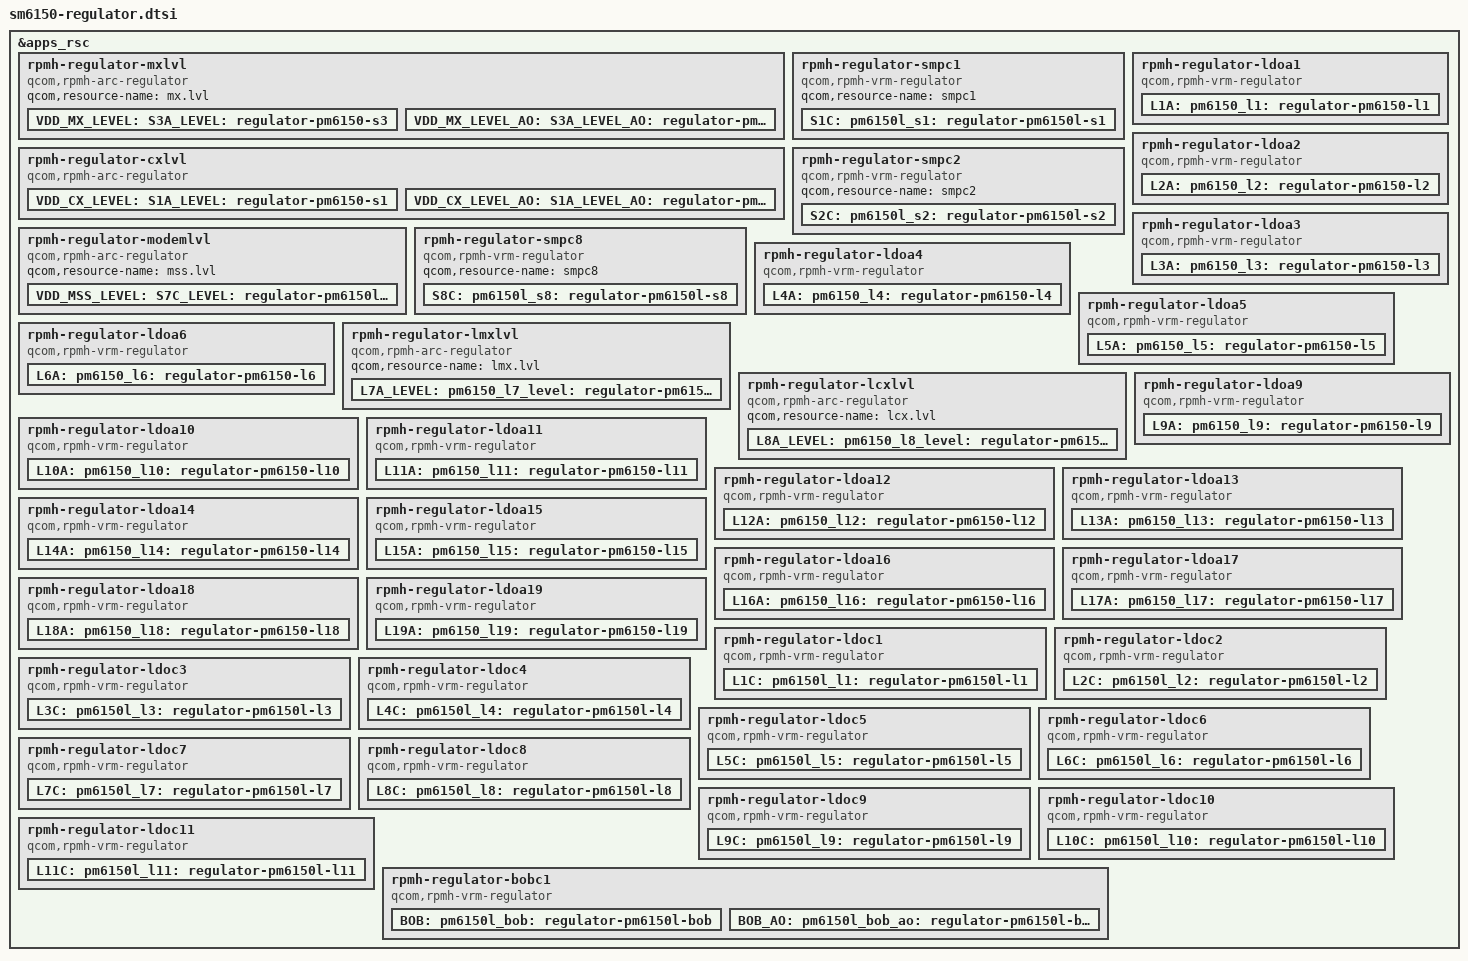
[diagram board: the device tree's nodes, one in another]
#include <dt-bindings/regulator/qcom,rpmh-regulator-levels.h>

&apps_rsc {
	/* RPMh regulators: */

	/* pm6150 S3 - VDD_MX supply */
	rpmh-regulator-mxlvl {
		compatible = "qcom,rpmh-arc-regulator";
		qcom,resource-name = "mx.lvl";

		VDD_MX_LEVEL:
		S3A_LEVEL: pm6150_s3_level: regulator-pm6150-s3 {
			regulator-name = "pm6150_s3_level";
			qcom,set = <RPMH_REGULATOR_SET_ALL>;
			regulator-min-microvolt =
					<RPMH_REGULATOR_LEVEL_RETENTION>;
			regulator-max-microvolt =
					<RPMH_REGULATOR_LEVEL_MAX>;
			qcom,init-voltage-level =
					<RPMH_REGULATOR_LEVEL_RETENTION>;
		};

		VDD_MX_LEVEL_AO:
		S3A_LEVEL_AO: pm6150_s3_level_ao: regulator-pm6150-s3-level-ao {
			regulator-name = "pm6150_s3_level_ao";
			qcom,set = <RPMH_REGULATOR_SET_ACTIVE>;
			regulator-min-microvolt =
					<RPMH_REGULATOR_LEVEL_RETENTION>;
			regulator-max-microvolt =
					<RPMH_REGULATOR_LEVEL_MAX>;
			qcom,init-voltage-level =
					<RPMH_REGULATOR_LEVEL_RETENTION>;
		};
	};

	/* pm6150 S1 - VDD_CX supply */
	rpmh-regulator-cxlvl {
		compatible = "qcom,rpmh-arc-regulator";
		qcom,resource-name = "cx.lvl";
		pm6150_s1_level-parent-supply = <&VDD_MX_LEVEL>;
		pm6150_s1_level_ao-parent-supply = <&VDD_MX_LEVEL_AO>;

		VDD_CX_LEVEL:
		S1A_LEVEL: pm6150_s1_level: regulator-pm6150-s1 {
			regulator-name = "pm6150_s1_level";
			qcom,set = <RPMH_REGULATOR_SET_ALL>;
			regulator-min-microvolt =
					<RPMH_REGULATOR_LEVEL_RETENTION>;
			regulator-max-microvolt =
					<RPMH_REGULATOR_LEVEL_MAX>;
			qcom,init-voltage-level =
					<RPMH_REGULATOR_LEVEL_RETENTION>;
			qcom,min-dropout-voltage-level = <(-1)>;
		};

		VDD_CX_LEVEL_AO:
		S1A_LEVEL_AO: pm6150_s1_level_ao: regulator-pm6150-s1-level-ao {
			qcom,set = <RPMH_REGULATOR_SET_ACTIVE>;
			regulator-name = "pm6150_s1_level_ao";
			regulator-min-microvolt =
					<RPMH_REGULATOR_LEVEL_RETENTION>;
			regulator-max-microvolt =
					<RPMH_REGULATOR_LEVEL_MAX>;
			qcom,init-voltage-level =
					<RPMH_REGULATOR_LEVEL_RETENTION>;
			qcom,min-dropout-voltage-level = <(-1)>;
		};
	};

	rpmh-regulator-smpc1 {
		compatible = "qcom,rpmh-vrm-regulator";
		qcom,resource-name = "smpc1";
		S1C: pm6150l_s1: regulator-pm6150l-s1 {
			regulator-name = "pm6150l_s1";
			qcom,set = <RPMH_REGULATOR_SET_ALL>;
			regulator-min-microvolt = <1128000>;
			regulator-max-microvolt = <1128000>;
			qcom,init-voltage = <1128000>;
		};
	};

	rpmh-regulator-smpc2 {
		compatible = "qcom,rpmh-vrm-regulator";
		qcom,resource-name = "smpc2";
		S2C: pm6150l_s2: regulator-pm6150l-s2 {
			regulator-name = "pm6150l_s2";
			qcom,set = <RPMH_REGULATOR_SET_ALL>;
			regulator-min-microvolt = <348000>;
			regulator-max-microvolt = <648000>;
			qcom,init-voltage = <348000>;
		};
	};

	/* pm6150l S7 - VDD_MSS supply */
	rpmh-regulator-modemlvl {
		compatible = "qcom,rpmh-arc-regulator";
		qcom,resource-name = "mss.lvl";

		VDD_MSS_LEVEL:
		S7C_LEVEL: pm6150l_s7_level: regulator-pm6150l-s7 {
			regulator-name = "pm6150l_s7_level";
			qcom,set = <RPMH_REGULATOR_SET_ALL>;
			regulator-min-microvolt =
					<RPMH_REGULATOR_LEVEL_RETENTION>;
			regulator-max-microvolt =
					<RPMH_REGULATOR_LEVEL_MAX>;
			qcom,init-voltage-level =
					<RPMH_REGULATOR_LEVEL_RETENTION>;
		};
	};

	rpmh-regulator-smpc8 {
		compatible = "qcom,rpmh-vrm-regulator";
		qcom,resource-name = "smpc8";
		S8C: pm6150l_s8: regulator-pm6150l-s8 {
			regulator-name = "pm6150l_s8";
			qcom,set = <RPMH_REGULATOR_SET_ALL>;
			regulator-min-microvolt = <1200000>;
			regulator-max-microvolt = <1400000>;
			qcom,init-voltage = <1200000>;
		};
	};

	rpmh-regulator-ldoa1 {
		compatible = "qcom,rpmh-vrm-regulator";
		qcom,resource-name = "ldoa1";
		qcom,regulator-type = "pmic5-ldo";
		qcom,supported-modes =
				<RPMH_REGULATOR_MODE_LPM
				RPMH_REGULATOR_MODE_HPM>;
		qcom,mode-threshold-currents = <0 1>;
		L1A: pm6150_l1: regulator-pm6150-l1 {
			regulator-name = "pm6150_l1";
			qcom,set = <RPMH_REGULATOR_SET_ALL>;
			regulator-min-microvolt = <1200000>;
			regulator-max-microvolt = <1252000>;
			qcom,init-voltage = <1200000>;
		};
	};

	rpmh-regulator-ldoa2 {
		compatible = "qcom,rpmh-vrm-regulator";
		qcom,resource-name = "ldoa2";
		qcom,regulator-type = "pmic5-ldo";
		qcom,supported-modes =
				<RPMH_REGULATOR_MODE_LPM
				RPMH_REGULATOR_MODE_HPM>;
		qcom,mode-threshold-currents = <0 1>;
		L2A: pm6150_l2: regulator-pm6150-l2 {
			regulator-name = "pm6150_l2";
			qcom,set = <RPMH_REGULATOR_SET_ALL>;
			regulator-min-microvolt = <1000000>;
			regulator-max-microvolt = <1050000>;
			qcom,init-voltage = <1000000>;
			qcom,init-mode = <RPMH_REGULATOR_MODE_LPM>;
		};
	};

	rpmh-regulator-ldoa3 {
		compatible = "qcom,rpmh-vrm-regulator";
		qcom,resource-name = "ldoa3";
		qcom,regulator-type = "pmic5-ldo";
		qcom,supported-modes =
				<RPMH_REGULATOR_MODE_LPM
				RPMH_REGULATOR_MODE_HPM>;
		qcom,mode-threshold-currents = <0 1>;
		L3A: pm6150_l3: regulator-pm6150-l3 {
			regulator-name = "pm6150_l3";
			qcom,set = <RPMH_REGULATOR_SET_ALL>;
			regulator-min-microvolt = <1000000>;
			regulator-max-microvolt = <1060000>;
			qcom,init-voltage = <1000000>;
			qcom,init-mode = <RPMH_REGULATOR_MODE_LPM>;
		};
	};

	rpmh-regulator-ldoa4 {
		compatible = "qcom,rpmh-vrm-regulator";
		qcom,resource-name = "ldoa4";
		qcom,regulator-type = "pmic5-ldo";
		qcom,supported-modes =
				<RPMH_REGULATOR_MODE_LPM
				RPMH_REGULATOR_MODE_HPM>;
		qcom,mode-threshold-currents = <0 1>;
		proxy-supply = <&pm6150_l4>;
		L4A: pm6150_l4: regulator-pm6150-l4 {
			regulator-name = "pm6150_l4";
			qcom,set = <RPMH_REGULATOR_SET_ALL>;
			regulator-min-microvolt = <875000>;
			regulator-max-microvolt = <975000>;
			qcom,init-voltage = <875000>;
			qcom,init-mode = <RPMH_REGULATOR_MODE_LPM>;
			qcom,proxy-consumer-enable;
			qcom,proxy-consumer-current = <23800>;
		};
	};

	rpmh-regulator-ldoa5 {
		compatible = "qcom,rpmh-vrm-regulator";
		qcom,resource-name = "ldoa5";
		qcom,regulator-type = "pmic5-ldo";
		qcom,supported-modes =
				<RPMH_REGULATOR_MODE_LPM
				RPMH_REGULATOR_MODE_HPM>;
		qcom,mode-threshold-currents = <0 1>;
		L5A: pm6150_l5: regulator-pm6150-l5 {
			regulator-name = "pm6150_l5";
			qcom,set = <RPMH_REGULATOR_SET_ALL>;
			regulator-min-microvolt = <2500000>;
			regulator-max-microvolt = <2970000>;
			qcom,init-voltage = <2500000>;
			qcom,init-mode = <RPMH_REGULATOR_MODE_LPM>;
		};
	};

	rpmh-regulator-ldoa6 {
		compatible = "qcom,rpmh-vrm-regulator";
		qcom,resource-name = "ldoa6";
		qcom,regulator-type = "pmic5-ldo";
		qcom,supported-modes =
				<RPMH_REGULATOR_MODE_LPM
				RPMH_REGULATOR_MODE_HPM>;
		qcom,mode-threshold-currents = <0 1>;
		L6A: pm6150_l6: regulator-pm6150-l6 {
			regulator-name = "pm6150_l6";
			qcom,set = <RPMH_REGULATOR_SET_ALL>;
			regulator-min-microvolt = <600000>;
			regulator-max-microvolt = <650000>;
			qcom,init-voltage = <600000>;
			qcom,init-mode = <RPMH_REGULATOR_MODE_LPM>;
		};
	};

	/* pm6150 L7 - LPI_MX supply */
	rpmh-regulator-lmxlvl {
		compatible = "qcom,rpmh-arc-regulator";
		qcom,resource-name = "lmx.lvl";
		L7A_LEVEL: pm6150_l7_level: regulator-pm6150-l7 {
			regulator-name = "pm6150_l7_level";
			qcom,set = <RPMH_REGULATOR_SET_ALL>;
			regulator-min-microvolt =
					<RPMH_REGULATOR_LEVEL_RETENTION>;
			regulator-max-microvolt =
					<RPMH_REGULATOR_LEVEL_MAX>;
			qcom,init-voltage-level =
					<RPMH_REGULATOR_LEVEL_RETENTION>;
		};
	};

	/* pm6150 L8 - LPI_CX supply */
	rpmh-regulator-lcxlvl {
		compatible = "qcom,rpmh-arc-regulator";
		qcom,resource-name = "lcx.lvl";
		L8A_LEVEL: pm6150_l8_level: regulator-pm6150-l8 {
			regulator-name = "pm6150_l8_level";
			qcom,set = <RPMH_REGULATOR_SET_ALL>;
			regulator-min-microvolt =
					<RPMH_REGULATOR_LEVEL_RETENTION>;
			regulator-max-microvolt =
					<RPMH_REGULATOR_LEVEL_MAX>;
			qcom,init-voltage-level =
					<RPMH_REGULATOR_LEVEL_RETENTION>;
		};
	};

	/* pm6150 L9 - WCSS_CX supply */
	rpmh-regulator-ldoa9 {
		compatible = "qcom,rpmh-vrm-regulator";
		qcom,resource-name = "ldoa9";
		qcom,regulator-type = "pmic5-ldo";
		qcom,supported-modes =
				<RPMH_REGULATOR_MODE_LPM
				RPMH_REGULATOR_MODE_HPM>;
		qcom,mode-threshold-currents = <0 1>;
		L9A: pm6150_l9: regulator-pm6150-l9 {
			regulator-name = "pm6150_l9";
			qcom,set = <RPMH_REGULATOR_SET_ALL>;
			regulator-min-microvolt = <400000>;
			regulator-max-microvolt = <728000>;
			qcom,init-voltage = <400000>;
			qcom,init-mode = <RPMH_REGULATOR_MODE_LPM>;
		};
	};

	rpmh-regulator-ldoa10 {
		compatible = "qcom,rpmh-vrm-regulator";
		qcom,resource-name = "ldoa10";
		qcom,regulator-type = "pmic5-ldo";
		qcom,supported-modes =
				<RPMH_REGULATOR_MODE_LPM
				RPMH_REGULATOR_MODE_HPM>;
		qcom,mode-threshold-currents = <0 1>;
		L10A: pm6150_l10: regulator-pm6150-l10 {
			regulator-name = "pm6150_l10";
			qcom,set = <RPMH_REGULATOR_SET_ALL>;
			regulator-min-microvolt = <1800000>;
			regulator-max-microvolt = <1829000>;
			qcom,init-voltage = <1800000>;
			qcom,init-mode = <RPMH_REGULATOR_MODE_LPM>;
		};
	};

	rpmh-regulator-ldoa11 {
		compatible = "qcom,rpmh-vrm-regulator";
		qcom,resource-name = "ldoa11";
		qcom,regulator-type = "pmic5-ldo";
		qcom,supported-modes =
				<RPMH_REGULATOR_MODE_LPM
				RPMH_REGULATOR_MODE_HPM>;
		qcom,mode-threshold-currents = <0 1>;
		L11A: pm6150_l11: regulator-pm6150-l11 {
			regulator-name = "pm6150_l11";
			qcom,set = <RPMH_REGULATOR_SET_ALL>;
			regulator-min-microvolt = <1800000>;
			regulator-max-microvolt = <1890000>;
			qcom,init-voltage = <1800000>;
			qcom,init-mode = <RPMH_REGULATOR_MODE_LPM>;
		};
	};

	rpmh-regulator-ldoa12 {
		compatible = "qcom,rpmh-vrm-regulator";
		qcom,resource-name = "ldoa12";
		qcom,regulator-type = "pmic5-ldo";
		qcom,supported-modes =
				<RPMH_REGULATOR_MODE_LPM
				RPMH_REGULATOR_MODE_HPM>;
		qcom,mode-threshold-currents = <0 1>;
		L12A: pm6150_l12: regulator-pm6150-l12 {
			regulator-name = "pm6150_l12";
			qcom,set = <RPMH_REGULATOR_SET_ALL>;
			regulator-min-microvolt = <1800000>;
			regulator-max-microvolt = <1950000>;
			qcom,init-voltage = <1800000>;
			qcom,init-mode = <RPMH_REGULATOR_MODE_LPM>;
		};
	};

	rpmh-regulator-ldoa13 {
		compatible = "qcom,rpmh-vrm-regulator";
		qcom,resource-name = "ldoa13";
		qcom,regulator-type = "pmic5-ldo";
		qcom,supported-modes =
				<RPMH_REGULATOR_MODE_LPM
				RPMH_REGULATOR_MODE_HPM>;
		qcom,mode-threshold-currents = <0 1>;
		proxy-supply = <&pm6150_l13>;
		L13A: pm6150_l13: regulator-pm6150-l13 {
			regulator-name = "pm6150_l13";
			qcom,set = <RPMH_REGULATOR_SET_ALL>;
			regulator-min-microvolt = <1800000>;
			regulator-max-microvolt = <1900000>;
			qcom,init-voltage = <1800000>;
			qcom,init-mode = <RPMH_REGULATOR_MODE_LPM>;
			qcom,proxy-consumer-enable;
			qcom,proxy-consumer-current = <115000>;
		};
	};

	rpmh-regulator-ldoa14 {
		compatible = "qcom,rpmh-vrm-regulator";
		qcom,resource-name = "ldoa14";
		qcom,regulator-type = "pmic5-ldo";
		qcom,supported-modes =
				<RPMH_REGULATOR_MODE_LPM
				RPMH_REGULATOR_MODE_HPM>;
		qcom,mode-threshold-currents = <0 1>;
		L14A: pm6150_l14: regulator-pm6150-l14 {
			regulator-name = "pm6150_l14";
			qcom,set = <RPMH_REGULATOR_SET_ALL>;
			regulator-min-microvolt = <1800000>;
			regulator-max-microvolt = <1850000>;
			qcom,init-voltage = <1800000>;
			qcom,init-mode = <RPMH_REGULATOR_MODE_LPM>;
		};
	};

	rpmh-regulator-ldoa15 {
		compatible = "qcom,rpmh-vrm-regulator";
		qcom,resource-name = "ldoa15";
		qcom,regulator-type = "pmic5-ldo";
		qcom,supported-modes =
				<RPMH_REGULATOR_MODE_LPM
				RPMH_REGULATOR_MODE_HPM>;
		qcom,mode-threshold-currents = <0 1>;
		L15A: pm6150_l15: regulator-pm6150-l15 {
			regulator-name = "pm6150_l15";
			qcom,set = <RPMH_REGULATOR_SET_ALL>;
			regulator-min-microvolt = <1800000>;
			regulator-max-microvolt = <1900000>;
			qcom,init-voltage = <1800000>;
			qcom,init-mode = <RPMH_REGULATOR_MODE_LPM>;
		};
	};

	rpmh-regulator-ldoa16 {
		compatible = "qcom,rpmh-vrm-regulator";
		qcom,resource-name = "ldoa16";
		qcom,regulator-type = "pmic5-ldo";
		qcom,supported-modes =
				<RPMH_REGULATOR_MODE_LPM
				RPMH_REGULATOR_MODE_HPM>;
		qcom,mode-threshold-currents = <0 1>;
		L16A: pm6150_l16: regulator-pm6150-l16 {
			regulator-name = "pm6150_l16";
			qcom,set = <RPMH_REGULATOR_SET_ALL>;
			regulator-min-microvolt = <2430000>;
			regulator-max-microvolt = <2970000>;
			qcom,init-voltage = <2430000>;
			qcom,init-mode = <RPMH_REGULATOR_MODE_LPM>;
		};
	};

	rpmh-regulator-ldoa17 {
		compatible = "qcom,rpmh-vrm-regulator";
		qcom,resource-name = "ldoa17";
		qcom,regulator-type = "pmic5-ldo";
		qcom,supported-modes =
				<RPMH_REGULATOR_MODE_LPM
				RPMH_REGULATOR_MODE_HPM>;
		qcom,mode-threshold-currents = <0 1>;
		L17A: pm6150_l17: regulator-pm6150-l17 {
			regulator-name = "pm6150_l17";
			qcom,set = <RPMH_REGULATOR_SET_ALL>;
			regulator-min-microvolt = <3000000>;
			regulator-max-microvolt = <3230000>;
			qcom,init-voltage = <3000000>;
			qcom,init-mode = <RPMH_REGULATOR_MODE_LPM>;
		};
	};

	rpmh-regulator-ldoa18 {
		compatible = "qcom,rpmh-vrm-regulator";
		qcom,resource-name = "ldoa18";
		qcom,regulator-type = "pmic5-ldo";
		qcom,supported-modes =
				<RPMH_REGULATOR_MODE_LPM
				RPMH_REGULATOR_MODE_HPM>;
		qcom,mode-threshold-currents = <0 1>;
		L18A: pm6150_l18: regulator-pm6150-l18 {
			regulator-name = "pm6150_l18";
			qcom,set = <RPMH_REGULATOR_SET_ALL>;
			regulator-min-microvolt = <3000000>;
			regulator-max-microvolt = <3008000>;
			qcom,init-voltage = <3000000>;
			qcom,init-mode = <RPMH_REGULATOR_MODE_LPM>;
		};
	};

	rpmh-regulator-ldoa19 {
		compatible = "qcom,rpmh-vrm-regulator";
		qcom,resource-name = "ldoa19";
		qcom,regulator-type = "pmic5-ldo";
		qcom,supported-modes =
				<RPMH_REGULATOR_MODE_LPM
				RPMH_REGULATOR_MODE_HPM>;
		qcom,mode-threshold-currents = <0 1>;
		L19A: pm6150_l19: regulator-pm6150-l19 {
			regulator-name = "pm6150_l19";
			qcom,set = <RPMH_REGULATOR_SET_ALL>;
			regulator-min-microvolt = <2700000>;
			regulator-max-microvolt = <3008000>;
			qcom,init-voltage = <2700000>;
			qcom,init-mode = <RPMH_REGULATOR_MODE_LPM>;
		};
	};

	rpmh-regulator-ldoc1 {
		compatible = "qcom,rpmh-vrm-regulator";
		qcom,resource-name = "ldoc1";
		qcom,regulator-type = "pmic5-ldo";
		qcom,supported-modes =
				<RPMH_REGULATOR_MODE_LPM
				RPMH_REGULATOR_MODE_HPM>;
		qcom,mode-threshold-currents = <0 10000>;
		L1C: pm6150l_l1: regulator-pm6150l-l1 {
			regulator-name = "pm6150l_l1";
			qcom,set = <RPMH_REGULATOR_SET_ALL>;
			regulator-min-microvolt = <1800000>;
			regulator-max-microvolt = <1900000>;
			qcom,init-voltage = <1800000>;
			qcom,init-mode = <RPMH_REGULATOR_MODE_LPM>;
		};
	};

	rpmh-regulator-ldoc2 {
		compatible = "qcom,rpmh-vrm-regulator";
		qcom,resource-name = "ldoc2";
		qcom,regulator-type = "pmic5-ldo";
		qcom,supported-modes =
				<RPMH_REGULATOR_MODE_LPM
				RPMH_REGULATOR_MODE_HPM>;
		qcom,mode-threshold-currents = <0 10000>;
		L2C: pm6150l_l2: regulator-pm6150l-l2 {
			regulator-name = "pm6150l_l2";
			qcom,set = <RPMH_REGULATOR_SET_ALL>;
			regulator-min-microvolt = <1304000>;
			regulator-max-microvolt = <1304000>;
			qcom,init-voltage = <1304000>;
			qcom,init-mode = <RPMH_REGULATOR_MODE_LPM>;
		};
	};

	rpmh-regulator-ldoc3 {
		compatible = "qcom,rpmh-vrm-regulator";
		qcom,resource-name = "ldoc3";
		qcom,regulator-type = "pmic5-ldo";
		qcom,supported-modes =
				<RPMH_REGULATOR_MODE_LPM
				RPMH_REGULATOR_MODE_HPM>;
		qcom,mode-threshold-currents = <0 1>;
		proxy-supply = <&pm6150l_l3>;
		L3C: pm6150l_l3: regulator-pm6150l-l3 {
			regulator-name = "pm6150l_l3";
			qcom,set = <RPMH_REGULATOR_SET_ALL>;
			regulator-min-microvolt = <1232000>;
			regulator-max-microvolt = <1260000>;
			qcom,init-voltage = <1232000>;
			qcom,init-mode = <RPMH_REGULATOR_MODE_LPM>;
			qcom,proxy-consumer-enable;
			qcom,proxy-consumer-current = <51800>;
		};
	};

	rpmh-regulator-ldoc4 {
		compatible = "qcom,rpmh-vrm-regulator";
		qcom,resource-name = "ldoc4";
		qcom,regulator-type = "pmic5-ldo";
		qcom,supported-modes =
				<RPMH_REGULATOR_MODE_LPM
				RPMH_REGULATOR_MODE_HPM>;
		qcom,mode-threshold-currents = <0 1>;
		L4C: pm6150l_l4: regulator-pm6150l-l4 {
			regulator-name = "pm6150l_l4";
			qcom,set = <RPMH_REGULATOR_SET_ALL>;
			regulator-min-microvolt = <1650000>;
			regulator-max-microvolt = <2950000>;
			qcom,init-voltage = <1650000>;
			qcom,init-mode = <RPMH_REGULATOR_MODE_LPM>;
		};
	};

	rpmh-regulator-ldoc5 {
		compatible = "qcom,rpmh-vrm-regulator";
		qcom,resource-name = "ldoc5";
		qcom,regulator-type = "pmic5-ldo";
		qcom,supported-modes =
				<RPMH_REGULATOR_MODE_LPM
				RPMH_REGULATOR_MODE_HPM>;
		qcom,mode-threshold-currents = <0 1>;
		L5C: pm6150l_l5: regulator-pm6150l-l5 {
			regulator-name = "pm6150l_l5";
			qcom,set = <RPMH_REGULATOR_SET_ALL>;
			regulator-min-microvolt = <1650000>;
			regulator-max-microvolt = <2950000>;
			qcom,init-voltage = <1650000>;
			qcom,init-mode = <RPMH_REGULATOR_MODE_LPM>;
		};
	};

	rpmh-regulator-ldoc6 {
		compatible = "qcom,rpmh-vrm-regulator";
		qcom,resource-name = "ldoc6";
		qcom,regulator-type = "pmic5-ldo";
		qcom,supported-modes =
				<RPMH_REGULATOR_MODE_LPM
				RPMH_REGULATOR_MODE_HPM>;
		qcom,mode-threshold-currents = <0 1>;
		L6C: pm6150l_l6: regulator-pm6150l-l6 {
			regulator-name = "pm6150l_l6";
			qcom,set = <RPMH_REGULATOR_SET_ALL>;
			regulator-min-microvolt = <1650000>;
			regulator-max-microvolt = <3100000>;
			qcom,init-voltage = <1650000>;
			qcom,init-mode = <RPMH_REGULATOR_MODE_LPM>;
		};
	};

	rpmh-regulator-ldoc7 {
		compatible = "qcom,rpmh-vrm-regulator";
		qcom,resource-name = "ldoc7";
		qcom,regulator-type = "pmic5-ldo";
		qcom,supported-modes =
				<RPMH_REGULATOR_MODE_LPM
				RPMH_REGULATOR_MODE_HPM>;
		qcom,mode-threshold-currents = <0 1>;
		L7C: pm6150l_l7: regulator-pm6150l-l7 {
			regulator-name = "pm6150l_l7";
			qcom,set = <RPMH_REGULATOR_SET_ALL>;
			regulator-min-microvolt = <3000000>;
			regulator-max-microvolt = <3312000>;
			qcom,init-voltage = <3000000>;
			qcom,init-mode = <RPMH_REGULATOR_MODE_LPM>;
		};
	};

	rpmh-regulator-ldoc8 {
		compatible = "qcom,rpmh-vrm-regulator";
		qcom,resource-name = "ldoc8";
		qcom,regulator-type = "pmic5-ldo";
		qcom,supported-modes =
				<RPMH_REGULATOR_MODE_LPM
				RPMH_REGULATOR_MODE_HPM>;
		qcom,mode-threshold-currents = <0 1>;
		L8C: pm6150l_l8: regulator-pm6150l-l8 {
			regulator-name = "pm6150l_l8";
			qcom,set = <RPMH_REGULATOR_SET_ALL>;
			regulator-min-microvolt = <1800000>;
			regulator-max-microvolt = <1900000>;
			qcom,init-voltage = <1800000>;
			qcom,init-mode = <RPMH_REGULATOR_MODE_LPM>;
		};
	};

	rpmh-regulator-ldoc9 {
		compatible = "qcom,rpmh-vrm-regulator";
		qcom,resource-name = "ldoc9";
		qcom,regulator-type = "pmic5-ldo";
		qcom,supported-modes =
				<RPMH_REGULATOR_MODE_LPM
				RPMH_REGULATOR_MODE_HPM>;
		qcom,mode-threshold-currents = <0 1>;
		L9C: pm6150l_l9: regulator-pm6150l-l9 {
			regulator-name = "pm6150l_l9";
			qcom,set = <RPMH_REGULATOR_SET_ALL>;
			regulator-min-microvolt = <2950000>;
			regulator-max-microvolt = <3312000>;
			qcom,init-voltage = <2950000>;
			qcom,init-mode = <RPMH_REGULATOR_MODE_LPM>;
		};
	};

	rpmh-regulator-ldoc10 {
		compatible = "qcom,rpmh-vrm-regulator";
		qcom,resource-name = "ldoc10";
		qcom,regulator-type = "pmic5-ldo";
		qcom,supported-modes =
				<RPMH_REGULATOR_MODE_LPM
				RPMH_REGULATOR_MODE_HPM>;
		qcom,mode-threshold-currents = <0 10000>;
		L10C: pm6150l_l10: regulator-pm6150l-l10 {
			regulator-name = "pm6150l_l10";
			qcom,set = <RPMH_REGULATOR_SET_ALL>;
			regulator-min-microvolt = <3200000>;
			regulator-max-microvolt = <3312000>;
			qcom,init-voltage = <3200000>;
			qcom,init-mode = <RPMH_REGULATOR_MODE_LPM>;
		};
	};

	rpmh-regulator-ldoc11 {
		compatible = "qcom,rpmh-vrm-regulator";
		qcom,resource-name = "ldoc11";
		qcom,regulator-type = "pmic5-ldo";
		qcom,supported-modes =
				<RPMH_REGULATOR_MODE_LPM
				RPMH_REGULATOR_MODE_HPM>;
		qcom,mode-threshold-currents = <0 1>;
		L11C: pm6150l_l11: regulator-pm6150l-l11 {
			regulator-name = "pm6150l_l11";
			qcom,set = <RPMH_REGULATOR_SET_ALL>;
			regulator-min-microvolt = <2950000>;
			regulator-max-microvolt = <3312000>;
			qcom,init-voltage = <2950000>;
			qcom,init-mode = <RPMH_REGULATOR_MODE_LPM>;
		};
	};

	rpmh-regulator-bobc1 {
		compatible = "qcom,rpmh-vrm-regulator";
		qcom,resource-name = "bobc1";
		qcom,regulator-type = "pmic5-bob";
		qcom,supported-modes =
			<RPMH_REGULATOR_MODE_PASS
			 RPMH_REGULATOR_MODE_LPM
			 RPMH_REGULATOR_MODE_HPM>;
		qcom,mode-threshold-currents = <0 1000000 2000000>;
		qcom,send-defaults;

		BOB: pm6150l_bob: regulator-pm6150l-bob {
			regulator-name = "pm6150l_bob";
			qcom,set = <RPMH_REGULATOR_SET_ALL>;
			regulator-min-microvolt = <3296000>;
			regulator-max-microvolt = <3960000>;
			qcom,init-voltage = <3296000>;
			qcom,init-mode = <RPMH_REGULATOR_MODE_PASS>;
		};

		BOB_AO: pm6150l_bob_ao: regulator-pm6150l-bob-ao {
			regulator-name = "pm6150l_bob_ao";
			qcom,set = <RPMH_REGULATOR_SET_ACTIVE>;
			regulator-min-microvolt = <3296000>;
			regulator-max-microvolt = <3960000>;
			qcom,init-voltage = <3296000>;
			qcom,init-mode = <RPMH_REGULATOR_MODE_AUTO>;
		};
	};
};
